VERSION ""

NS_ :

BS_:

BU_: Hybrid Engine

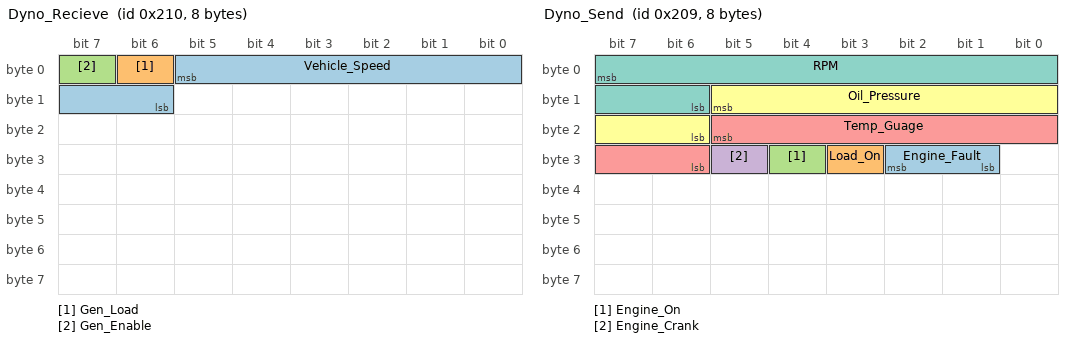
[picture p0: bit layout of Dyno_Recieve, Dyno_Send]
BO_ 528 Dyno_Recieve: 8 Vector__XXX
 SG_ Vehicle_Speed : 5|8@0+ (1,0) [0|0] "MPH" Vector__XXX
 SG_ Gen_Load : 6|1@0+ (1,0) [0|0] "" Vector__XXX
 SG_ Gen_Enable : 7|1@0+ (1,0) [0|0] "" Vector__XXX

BO_ 521 Dyno_Send: 8 Engine
 SG_ Engine_Fault : 26|2@0+ (1,0) [0|3] ""  Hybrid
 SG_ Load_On : 27|1@0+ (1,0) [0|0] ""  Hybrid
 SG_ Engine_On : 28|1@0+ (1,0) [0|0] ""  Hybrid
 SG_ Engine_Crank : 29|1@0+ (1,0) [0|0] ""  Hybrid
 SG_ Temp_Guage : 21|8@0+ (1,-40) [-40|215] "C"  Hybrid
 SG_ Oil_Pressure : 13|8@0+ (1,0) [0|255] "KPA"  Hybrid
 SG_ RPM : 7|10@0+ (10,0) [0|10230] "RPM"  Hybrid

BA_DEF_ SG_  "GenSigSendType" ENUM  "Cyclic","OnWrite","OnWriteWithRepetition","OnChange","OnChangeWithRepetition","IfActive","IfActiveWithRepetition","NoSigSendType";
BA_DEF_ BO_  "GenMsgCycleTime" INT 0 0;
BA_DEF_ BO_  "GenMsgSendType" ENUM  "Cyclic","not_used","not_used","not_used","not_used","Cyclic","not_used","IfActive","NoMsgSendType";
BA_DEF_  "DBName" STRING ;
BA_DEF_  "BusType" STRING ;
BA_DEF_DEF_  "GenSigSendType" "Cyclic";
BA_DEF_DEF_  "GenMsgCycleTime" 0;
BA_DEF_DEF_  "GenMsgSendType" "NoMsgSendType";
BA_DEF_DEF_  "DBName" "";
BA_DEF_DEF_  "BusType" "CAN";
BA_ "DBName" "DYNO";
BA_ "GenMsgSendType" BO_ 521 0;
BA_ "GenMsgCycleTime" BO_ 521 100;
